VERSION "ZephyrECU CI fixtures"
NS_ :

BS_:
BU_: ECU Tester

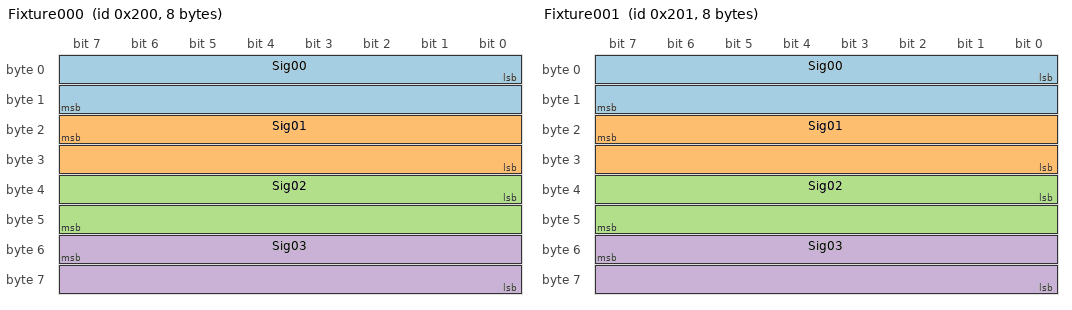
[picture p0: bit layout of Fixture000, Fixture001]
BO_ 512 Fixture000: 8 ECU
 SG_ Sig00 : 0|16@1+ (1,0) [0|65535] "" Tester
 SG_ Sig01 : 23|16@0- (1,0) [-32768|32767] "" Tester
 SG_ Sig02 : 32|16@1+ (1,0) [0|65535] "" Tester
 SG_ Sig03 : 55|16@0- (1,0) [-32768|32767] "" Tester

BO_ 513 Fixture001: 8 Tester
 SG_ Sig00 : 0|16@1+ (1,0) [0|65535] "" ECU
 SG_ Sig01 : 23|16@0- (1,0) [-32768|32767] "" ECU
 SG_ Sig02 : 32|16@1+ (1,0) [0|65535] "" ECU
 SG_ Sig03 : 55|16@0- (1,0) [-32768|32767] "" ECU

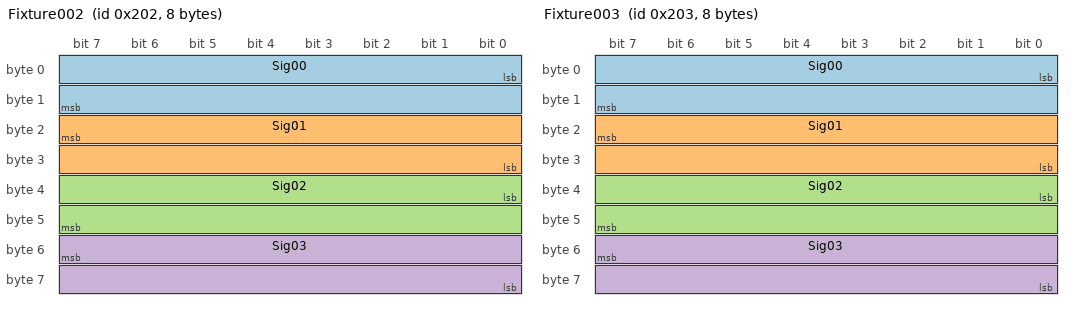
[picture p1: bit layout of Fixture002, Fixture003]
BO_ 514 Fixture002: 8 ECU
 SG_ Sig00 : 0|16@1+ (1,0) [0|65535] "" Tester
 SG_ Sig01 : 23|16@0- (1,0) [-32768|32767] "" Tester
 SG_ Sig02 : 32|16@1+ (1,0) [0|65535] "" Tester
 SG_ Sig03 : 55|16@0- (1,0) [-32768|32767] "" Tester

BO_ 515 Fixture003: 8 Tester
 SG_ Sig00 : 0|16@1+ (1,0) [0|65535] "" ECU
 SG_ Sig01 : 23|16@0- (1,0) [-32768|32767] "" ECU
 SG_ Sig02 : 32|16@1+ (1,0) [0|65535] "" ECU
 SG_ Sig03 : 55|16@0- (1,0) [-32768|32767] "" ECU

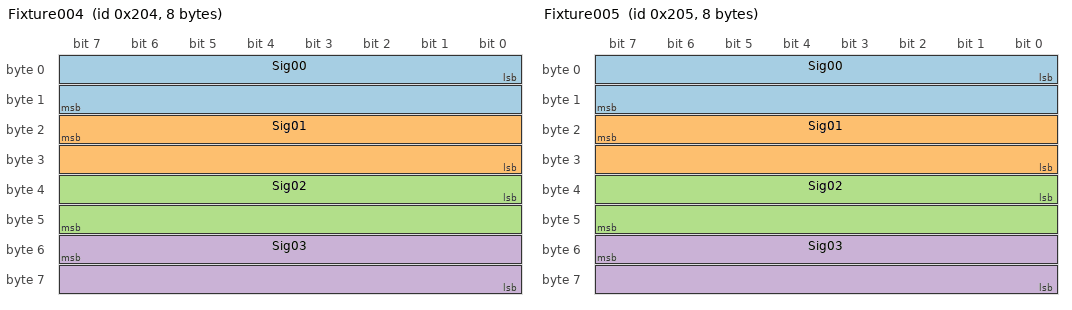
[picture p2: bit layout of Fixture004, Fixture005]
BO_ 516 Fixture004: 8 ECU
 SG_ Sig00 : 0|16@1+ (1,0) [0|65535] "" Tester
 SG_ Sig01 : 23|16@0- (1,0) [-32768|32767] "" Tester
 SG_ Sig02 : 32|16@1+ (1,0) [0|65535] "" Tester
 SG_ Sig03 : 55|16@0- (1,0) [-32768|32767] "" Tester

BO_ 517 Fixture005: 8 Tester
 SG_ Sig00 : 0|16@1+ (1,0) [0|65535] "" ECU
 SG_ Sig01 : 23|16@0- (1,0) [-32768|32767] "" ECU
 SG_ Sig02 : 32|16@1+ (1,0) [0|65535] "" ECU
 SG_ Sig03 : 55|16@0- (1,0) [-32768|32767] "" ECU

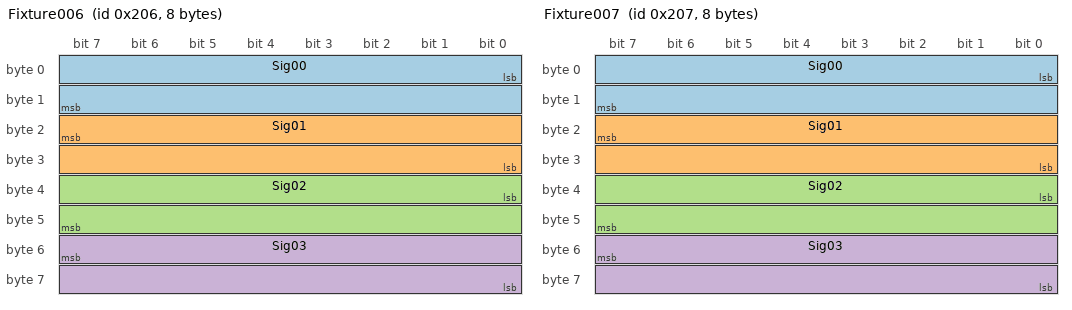
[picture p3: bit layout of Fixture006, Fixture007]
BO_ 518 Fixture006: 8 ECU
 SG_ Sig00 : 0|16@1+ (1,0) [0|65535] "" Tester
 SG_ Sig01 : 23|16@0- (1,0) [-32768|32767] "" Tester
 SG_ Sig02 : 32|16@1+ (1,0) [0|65535] "" Tester
 SG_ Sig03 : 55|16@0- (1,0) [-32768|32767] "" Tester

BO_ 519 Fixture007: 8 Tester
 SG_ Sig00 : 0|16@1+ (1,0) [0|65535] "" ECU
 SG_ Sig01 : 23|16@0- (1,0) [-32768|32767] "" ECU
 SG_ Sig02 : 32|16@1+ (1,0) [0|65535] "" ECU
 SG_ Sig03 : 55|16@0- (1,0) [-32768|32767] "" ECU

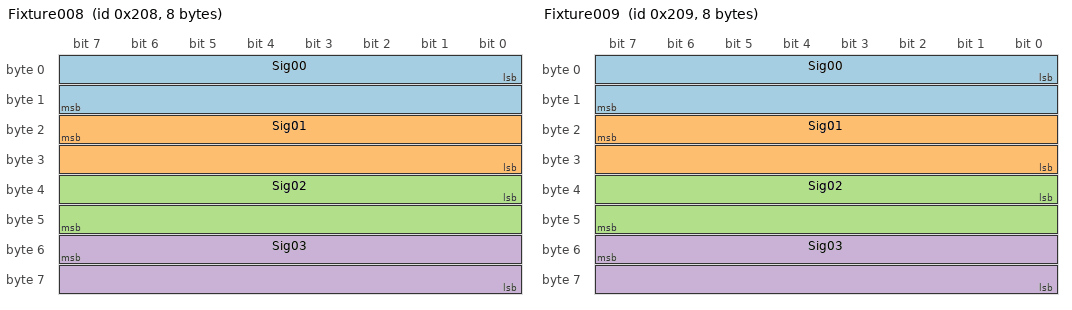
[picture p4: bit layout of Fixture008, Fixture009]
BO_ 520 Fixture008: 8 ECU
 SG_ Sig00 : 0|16@1+ (1,0) [0|65535] "" Tester
 SG_ Sig01 : 23|16@0- (1,0) [-32768|32767] "" Tester
 SG_ Sig02 : 32|16@1+ (1,0) [0|65535] "" Tester
 SG_ Sig03 : 55|16@0- (1,0) [-32768|32767] "" Tester

BO_ 521 Fixture009: 8 Tester
 SG_ Sig00 : 0|16@1+ (1,0) [0|65535] "" ECU
 SG_ Sig01 : 23|16@0- (1,0) [-32768|32767] "" ECU
 SG_ Sig02 : 32|16@1+ (1,0) [0|65535] "" ECU
 SG_ Sig03 : 55|16@0- (1,0) [-32768|32767] "" ECU

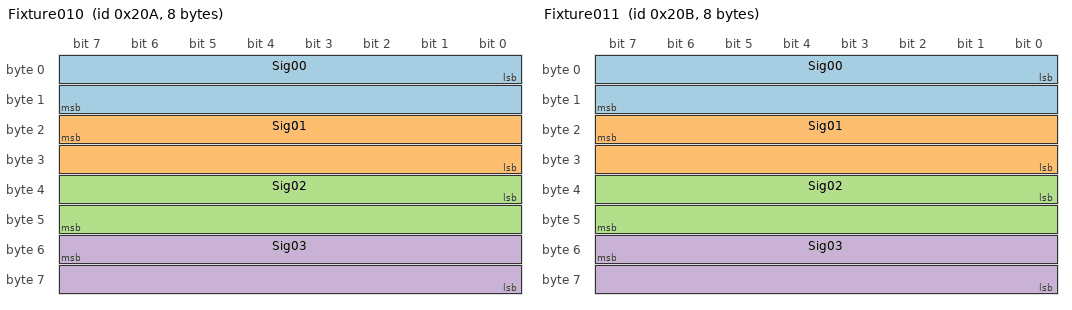
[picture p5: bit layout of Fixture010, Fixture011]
BO_ 522 Fixture010: 8 ECU
 SG_ Sig00 : 0|16@1+ (1,0) [0|65535] "" Tester
 SG_ Sig01 : 23|16@0- (1,0) [-32768|32767] "" Tester
 SG_ Sig02 : 32|16@1+ (1,0) [0|65535] "" Tester
 SG_ Sig03 : 55|16@0- (1,0) [-32768|32767] "" Tester

BO_ 523 Fixture011: 8 Tester
 SG_ Sig00 : 0|16@1+ (1,0) [0|65535] "" ECU
 SG_ Sig01 : 23|16@0- (1,0) [-32768|32767] "" ECU
 SG_ Sig02 : 32|16@1+ (1,0) [0|65535] "" ECU
 SG_ Sig03 : 55|16@0- (1,0) [-32768|32767] "" ECU

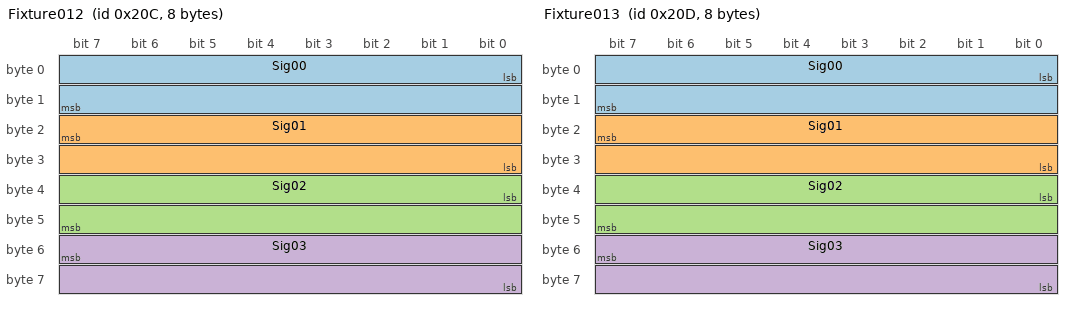
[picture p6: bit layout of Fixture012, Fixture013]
BO_ 524 Fixture012: 8 ECU
 SG_ Sig00 : 0|16@1+ (1,0) [0|65535] "" Tester
 SG_ Sig01 : 23|16@0- (1,0) [-32768|32767] "" Tester
 SG_ Sig02 : 32|16@1+ (1,0) [0|65535] "" Tester
 SG_ Sig03 : 55|16@0- (1,0) [-32768|32767] "" Tester

BO_ 525 Fixture013: 8 Tester
 SG_ Sig00 : 0|16@1+ (1,0) [0|65535] "" ECU
 SG_ Sig01 : 23|16@0- (1,0) [-32768|32767] "" ECU
 SG_ Sig02 : 32|16@1+ (1,0) [0|65535] "" ECU
 SG_ Sig03 : 55|16@0- (1,0) [-32768|32767] "" ECU

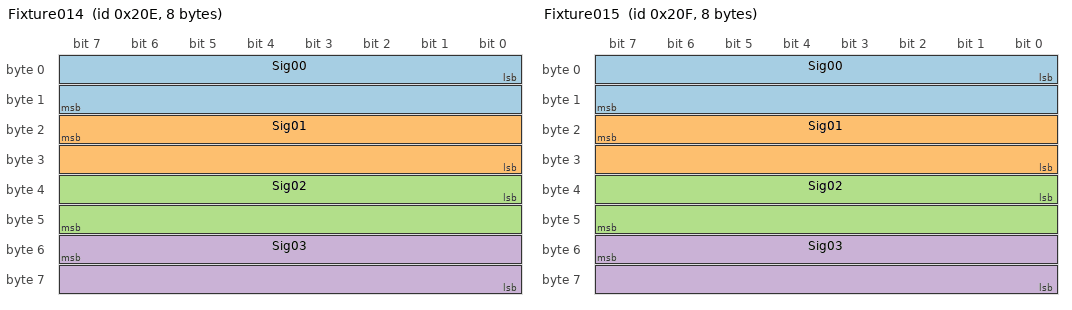
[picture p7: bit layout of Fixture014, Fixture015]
BO_ 526 Fixture014: 8 ECU
 SG_ Sig00 : 0|16@1+ (1,0) [0|65535] "" Tester
 SG_ Sig01 : 23|16@0- (1,0) [-32768|32767] "" Tester
 SG_ Sig02 : 32|16@1+ (1,0) [0|65535] "" Tester
 SG_ Sig03 : 55|16@0- (1,0) [-32768|32767] "" Tester

BO_ 527 Fixture015: 8 Tester
 SG_ Sig00 : 0|16@1+ (1,0) [0|65535] "" ECU
 SG_ Sig01 : 23|16@0- (1,0) [-32768|32767] "" ECU
 SG_ Sig02 : 32|16@1+ (1,0) [0|65535] "" ECU
 SG_ Sig03 : 55|16@0- (1,0) [-32768|32767] "" ECU

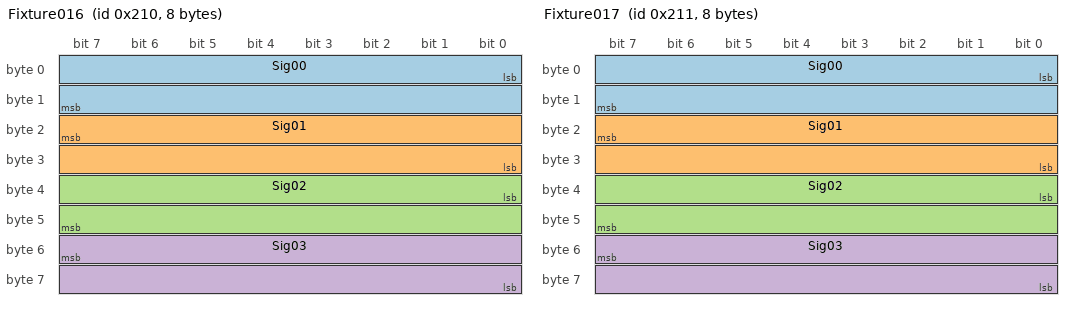
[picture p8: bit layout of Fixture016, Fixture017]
BO_ 528 Fixture016: 8 ECU
 SG_ Sig00 : 0|16@1+ (1,0) [0|65535] "" Tester
 SG_ Sig01 : 23|16@0- (1,0) [-32768|32767] "" Tester
 SG_ Sig02 : 32|16@1+ (1,0) [0|65535] "" Tester
 SG_ Sig03 : 55|16@0- (1,0) [-32768|32767] "" Tester

BO_ 529 Fixture017: 8 Tester
 SG_ Sig00 : 0|16@1+ (1,0) [0|65535] "" ECU
 SG_ Sig01 : 23|16@0- (1,0) [-32768|32767] "" ECU
 SG_ Sig02 : 32|16@1+ (1,0) [0|65535] "" ECU
 SG_ Sig03 : 55|16@0- (1,0) [-32768|32767] "" ECU

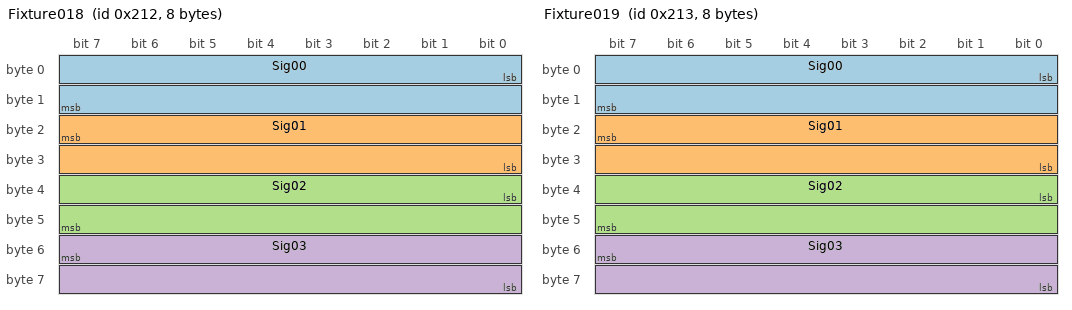
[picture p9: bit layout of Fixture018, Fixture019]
BO_ 530 Fixture018: 8 ECU
 SG_ Sig00 : 0|16@1+ (1,0) [0|65535] "" Tester
 SG_ Sig01 : 23|16@0- (1,0) [-32768|32767] "" Tester
 SG_ Sig02 : 32|16@1+ (1,0) [0|65535] "" Tester
 SG_ Sig03 : 55|16@0- (1,0) [-32768|32767] "" Tester

BO_ 531 Fixture019: 8 Tester
 SG_ Sig00 : 0|16@1+ (1,0) [0|65535] "" ECU
 SG_ Sig01 : 23|16@0- (1,0) [-32768|32767] "" ECU
 SG_ Sig02 : 32|16@1+ (1,0) [0|65535] "" ECU
 SG_ Sig03 : 55|16@0- (1,0) [-32768|32767] "" ECU

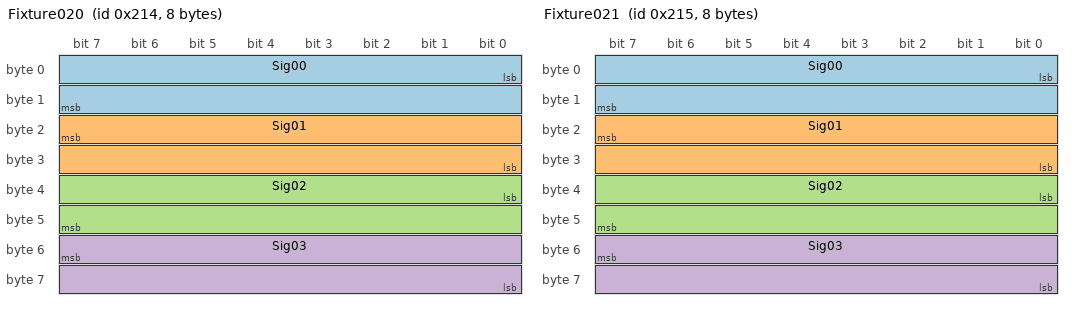
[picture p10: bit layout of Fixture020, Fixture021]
BO_ 532 Fixture020: 8 ECU
 SG_ Sig00 : 0|16@1+ (1,0) [0|65535] "" Tester
 SG_ Sig01 : 23|16@0- (1,0) [-32768|32767] "" Tester
 SG_ Sig02 : 32|16@1+ (1,0) [0|65535] "" Tester
 SG_ Sig03 : 55|16@0- (1,0) [-32768|32767] "" Tester

BO_ 533 Fixture021: 8 Tester
 SG_ Sig00 : 0|16@1+ (1,0) [0|65535] "" ECU
 SG_ Sig01 : 23|16@0- (1,0) [-32768|32767] "" ECU
 SG_ Sig02 : 32|16@1+ (1,0) [0|65535] "" ECU
 SG_ Sig03 : 55|16@0- (1,0) [-32768|32767] "" ECU

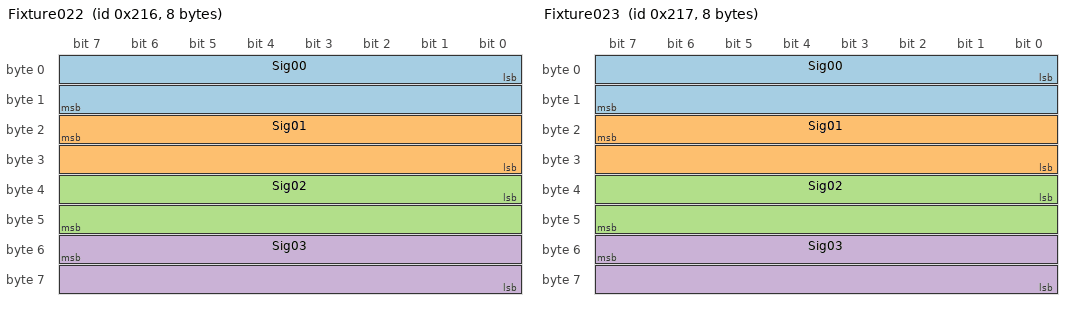
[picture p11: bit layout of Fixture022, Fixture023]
BO_ 534 Fixture022: 8 ECU
 SG_ Sig00 : 0|16@1+ (1,0) [0|65535] "" Tester
 SG_ Sig01 : 23|16@0- (1,0) [-32768|32767] "" Tester
 SG_ Sig02 : 32|16@1+ (1,0) [0|65535] "" Tester
 SG_ Sig03 : 55|16@0- (1,0) [-32768|32767] "" Tester

BO_ 535 Fixture023: 8 Tester
 SG_ Sig00 : 0|16@1+ (1,0) [0|65535] "" ECU
 SG_ Sig01 : 23|16@0- (1,0) [-32768|32767] "" ECU
 SG_ Sig02 : 32|16@1+ (1,0) [0|65535] "" ECU
 SG_ Sig03 : 55|16@0- (1,0) [-32768|32767] "" ECU

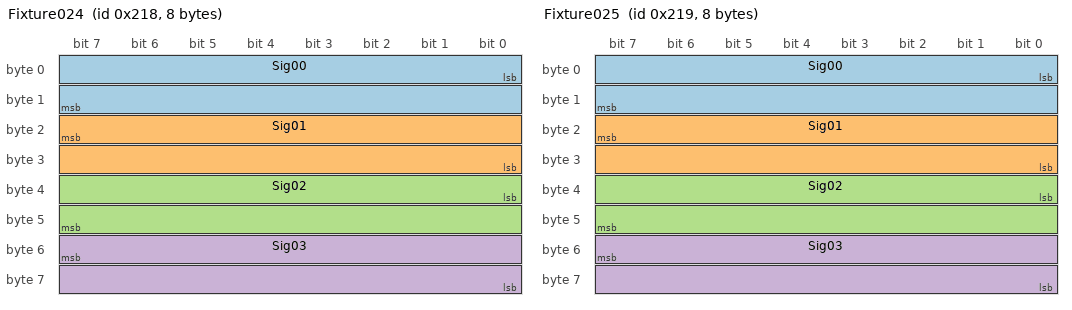
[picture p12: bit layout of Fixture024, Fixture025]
BO_ 536 Fixture024: 8 ECU
 SG_ Sig00 : 0|16@1+ (1,0) [0|65535] "" Tester
 SG_ Sig01 : 23|16@0- (1,0) [-32768|32767] "" Tester
 SG_ Sig02 : 32|16@1+ (1,0) [0|65535] "" Tester
 SG_ Sig03 : 55|16@0- (1,0) [-32768|32767] "" Tester

BO_ 537 Fixture025: 8 Tester
 SG_ Sig00 : 0|16@1+ (1,0) [0|65535] "" ECU
 SG_ Sig01 : 23|16@0- (1,0) [-32768|32767] "" ECU
 SG_ Sig02 : 32|16@1+ (1,0) [0|65535] "" ECU
 SG_ Sig03 : 55|16@0- (1,0) [-32768|32767] "" ECU

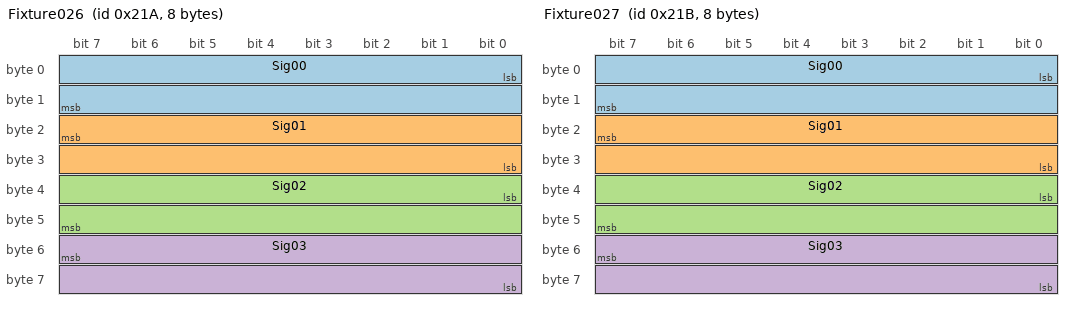
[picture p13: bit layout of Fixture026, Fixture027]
BO_ 538 Fixture026: 8 ECU
 SG_ Sig00 : 0|16@1+ (1,0) [0|65535] "" Tester
 SG_ Sig01 : 23|16@0- (1,0) [-32768|32767] "" Tester
 SG_ Sig02 : 32|16@1+ (1,0) [0|65535] "" Tester
 SG_ Sig03 : 55|16@0- (1,0) [-32768|32767] "" Tester

BO_ 539 Fixture027: 8 Tester
 SG_ Sig00 : 0|16@1+ (1,0) [0|65535] "" ECU
 SG_ Sig01 : 23|16@0- (1,0) [-32768|32767] "" ECU
 SG_ Sig02 : 32|16@1+ (1,0) [0|65535] "" ECU
 SG_ Sig03 : 55|16@0- (1,0) [-32768|32767] "" ECU

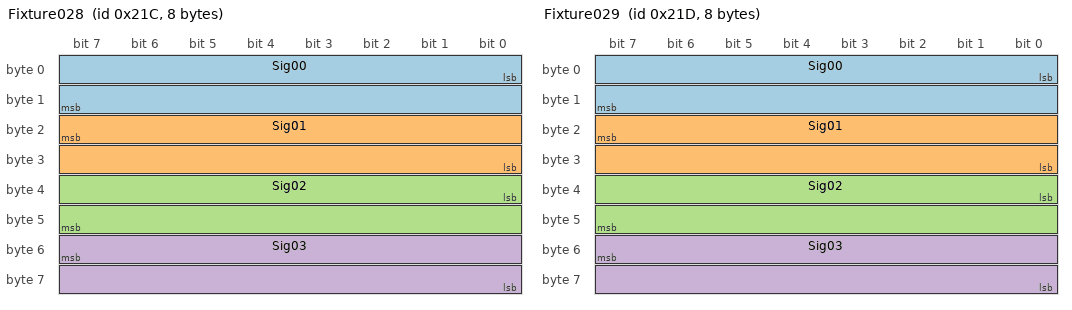
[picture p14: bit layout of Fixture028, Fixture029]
BO_ 540 Fixture028: 8 ECU
 SG_ Sig00 : 0|16@1+ (1,0) [0|65535] "" Tester
 SG_ Sig01 : 23|16@0- (1,0) [-32768|32767] "" Tester
 SG_ Sig02 : 32|16@1+ (1,0) [0|65535] "" Tester
 SG_ Sig03 : 55|16@0- (1,0) [-32768|32767] "" Tester

BO_ 541 Fixture029: 8 Tester
 SG_ Sig00 : 0|16@1+ (1,0) [0|65535] "" ECU
 SG_ Sig01 : 23|16@0- (1,0) [-32768|32767] "" ECU
 SG_ Sig02 : 32|16@1+ (1,0) [0|65535] "" ECU
 SG_ Sig03 : 55|16@0- (1,0) [-32768|32767] "" ECU

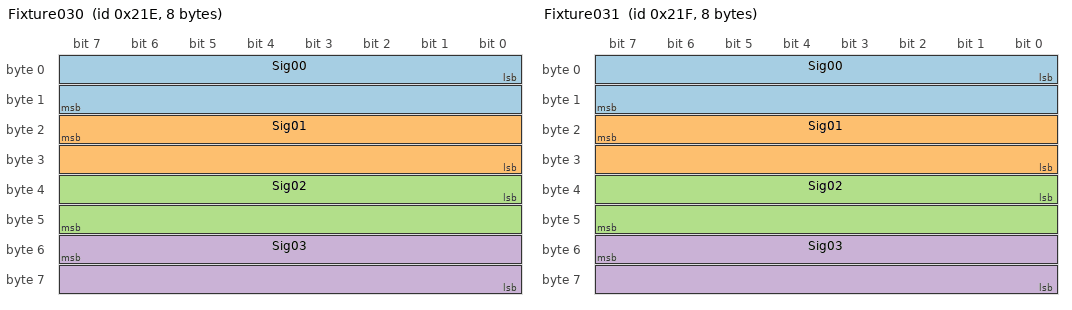
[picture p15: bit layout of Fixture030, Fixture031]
BO_ 542 Fixture030: 8 ECU
 SG_ Sig00 : 0|16@1+ (1,0) [0|65535] "" Tester
 SG_ Sig01 : 23|16@0- (1,0) [-32768|32767] "" Tester
 SG_ Sig02 : 32|16@1+ (1,0) [0|65535] "" Tester
 SG_ Sig03 : 55|16@0- (1,0) [-32768|32767] "" Tester

BO_ 543 Fixture031: 8 Tester
 SG_ Sig00 : 0|16@1+ (1,0) [0|65535] "" ECU
 SG_ Sig01 : 23|16@0- (1,0) [-32768|32767] "" ECU
 SG_ Sig02 : 32|16@1+ (1,0) [0|65535] "" ECU
 SG_ Sig03 : 55|16@0- (1,0) [-32768|32767] "" ECU

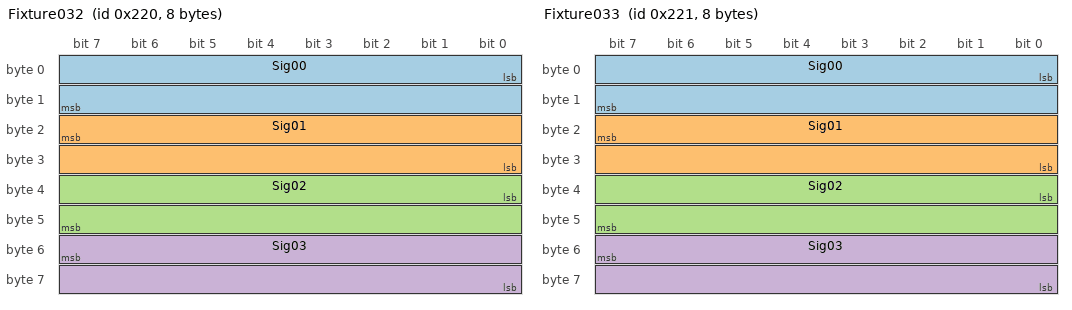
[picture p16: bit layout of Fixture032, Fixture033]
BO_ 544 Fixture032: 8 ECU
 SG_ Sig00 : 0|16@1+ (1,0) [0|65535] "" Tester
 SG_ Sig01 : 23|16@0- (1,0) [-32768|32767] "" Tester
 SG_ Sig02 : 32|16@1+ (1,0) [0|65535] "" Tester
 SG_ Sig03 : 55|16@0- (1,0) [-32768|32767] "" Tester

BO_ 545 Fixture033: 8 Tester
 SG_ Sig00 : 0|16@1+ (1,0) [0|65535] "" ECU
 SG_ Sig01 : 23|16@0- (1,0) [-32768|32767] "" ECU
 SG_ Sig02 : 32|16@1+ (1,0) [0|65535] "" ECU
 SG_ Sig03 : 55|16@0- (1,0) [-32768|32767] "" ECU

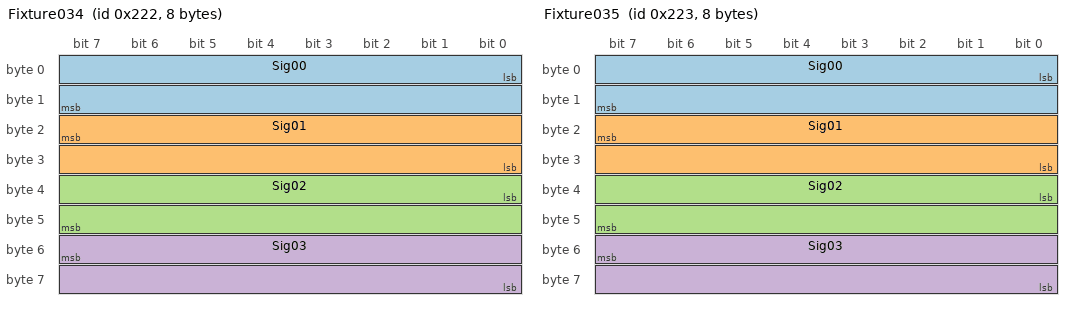
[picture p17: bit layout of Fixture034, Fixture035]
BO_ 546 Fixture034: 8 ECU
 SG_ Sig00 : 0|16@1+ (1,0) [0|65535] "" Tester
 SG_ Sig01 : 23|16@0- (1,0) [-32768|32767] "" Tester
 SG_ Sig02 : 32|16@1+ (1,0) [0|65535] "" Tester
 SG_ Sig03 : 55|16@0- (1,0) [-32768|32767] "" Tester

BO_ 547 Fixture035: 8 Tester
 SG_ Sig00 : 0|16@1+ (1,0) [0|65535] "" ECU
 SG_ Sig01 : 23|16@0- (1,0) [-32768|32767] "" ECU
 SG_ Sig02 : 32|16@1+ (1,0) [0|65535] "" ECU
 SG_ Sig03 : 55|16@0- (1,0) [-32768|32767] "" ECU

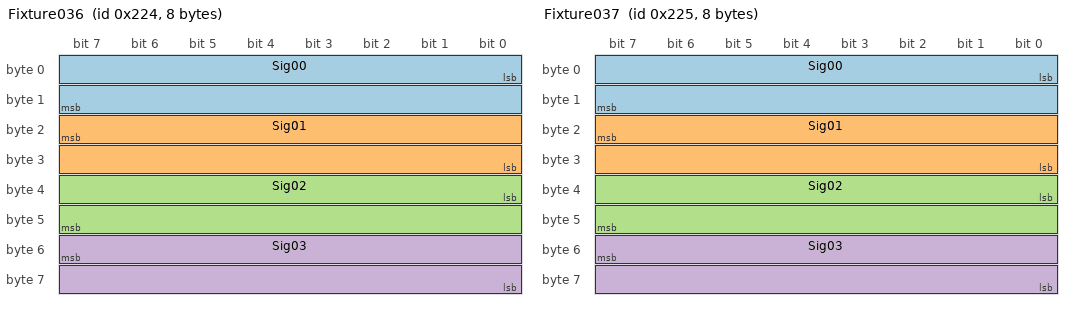
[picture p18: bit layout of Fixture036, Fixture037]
BO_ 548 Fixture036: 8 ECU
 SG_ Sig00 : 0|16@1+ (1,0) [0|65535] "" Tester
 SG_ Sig01 : 23|16@0- (1,0) [-32768|32767] "" Tester
 SG_ Sig02 : 32|16@1+ (1,0) [0|65535] "" Tester
 SG_ Sig03 : 55|16@0- (1,0) [-32768|32767] "" Tester

BO_ 549 Fixture037: 8 Tester
 SG_ Sig00 : 0|16@1+ (1,0) [0|65535] "" ECU
 SG_ Sig01 : 23|16@0- (1,0) [-32768|32767] "" ECU
 SG_ Sig02 : 32|16@1+ (1,0) [0|65535] "" ECU
 SG_ Sig03 : 55|16@0- (1,0) [-32768|32767] "" ECU

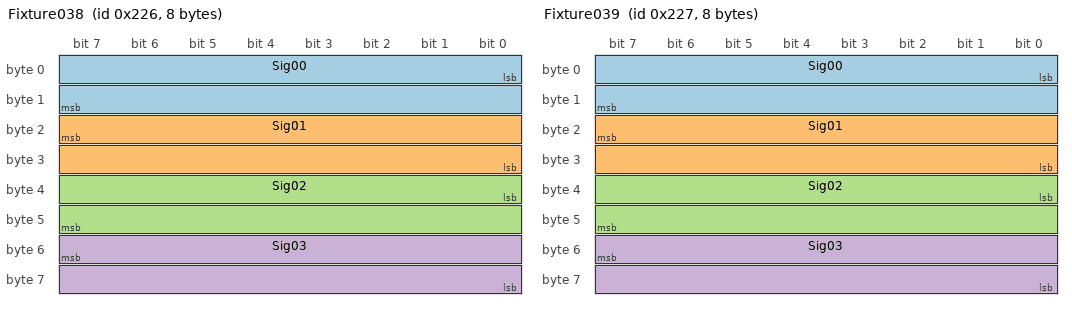
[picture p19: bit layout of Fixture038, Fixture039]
BO_ 550 Fixture038: 8 ECU
 SG_ Sig00 : 0|16@1+ (1,0) [0|65535] "" Tester
 SG_ Sig01 : 23|16@0- (1,0) [-32768|32767] "" Tester
 SG_ Sig02 : 32|16@1+ (1,0) [0|65535] "" Tester
 SG_ Sig03 : 55|16@0- (1,0) [-32768|32767] "" Tester

BO_ 551 Fixture039: 8 Tester
 SG_ Sig00 : 0|16@1+ (1,0) [0|65535] "" ECU
 SG_ Sig01 : 23|16@0- (1,0) [-32768|32767] "" ECU
 SG_ Sig02 : 32|16@1+ (1,0) [0|65535] "" ECU
 SG_ Sig03 : 55|16@0- (1,0) [-32768|32767] "" ECU

BO_ 552 Fixture040: 8 ECU
 SG_ Sig00 : 0|16@1+ (1,0) [0|65535] "" Tester
 SG_ Sig01 : 23|16@0- (1,0) [-32768|32767] "" Tester
 SG_ Sig02 : 32|16@1+ (1,0) [0|65535] "" Tester
 SG_ Sig03 : 55|16@0- (1,0) [-32768|32767] "" Tester

BO_ 553 Fixture041: 8 Tester
 SG_ Sig00 : 0|16@1+ (1,0) [0|65535] "" ECU
 SG_ Sig01 : 23|16@0- (1,0) [-32768|32767] "" ECU
 SG_ Sig02 : 32|16@1+ (1,0) [0|65535] "" ECU
 SG_ Sig03 : 55|16@0- (1,0) [-32768|32767] "" ECU

BO_ 554 Fixture042: 8 ECU
 SG_ Sig00 : 0|16@1+ (1,0) [0|65535] "" Tester
 SG_ Sig01 : 23|16@0- (1,0) [-32768|32767] "" Tester
 SG_ Sig02 : 32|16@1+ (1,0) [0|65535] "" Tester
 SG_ Sig03 : 55|16@0- (1,0) [-32768|32767] "" Tester

BO_ 555 Fixture043: 8 Tester
 SG_ Sig00 : 0|16@1+ (1,0) [0|65535] "" ECU
 SG_ Sig01 : 23|16@0- (1,0) [-32768|32767] "" ECU
 SG_ Sig02 : 32|16@1+ (1,0) [0|65535] "" ECU
 SG_ Sig03 : 55|16@0- (1,0) [-32768|32767] "" ECU

BO_ 556 Fixture044: 8 ECU
 SG_ Sig00 : 0|16@1+ (1,0) [0|65535] "" Tester
 SG_ Sig01 : 23|16@0- (1,0) [-32768|32767] "" Tester
 SG_ Sig02 : 32|16@1+ (1,0) [0|65535] "" Tester
 SG_ Sig03 : 55|16@0- (1,0) [-32768|32767] "" Tester

BO_ 557 Fixture045: 8 Tester
 SG_ Sig00 : 0|16@1+ (1,0) [0|65535] "" ECU
 SG_ Sig01 : 23|16@0- (1,0) [-32768|32767] "" ECU
 SG_ Sig02 : 32|16@1+ (1,0) [0|65535] "" ECU
 SG_ Sig03 : 55|16@0- (1,0) [-32768|32767] "" ECU

BO_ 558 Fixture046: 8 ECU
 SG_ Sig00 : 0|16@1+ (1,0) [0|65535] "" Tester
 SG_ Sig01 : 23|16@0- (1,0) [-32768|32767] "" Tester
 SG_ Sig02 : 32|16@1+ (1,0) [0|65535] "" Tester
 SG_ Sig03 : 55|16@0- (1,0) [-32768|32767] "" Tester

BO_ 559 Fixture047: 8 Tester
 SG_ Sig00 : 0|16@1+ (1,0) [0|65535] "" ECU
 SG_ Sig01 : 23|16@0- (1,0) [-32768|32767] "" ECU
 SG_ Sig02 : 32|16@1+ (1,0) [0|65535] "" ECU
 SG_ Sig03 : 55|16@0- (1,0) [-32768|32767] "" ECU

BO_ 560 Fixture048: 8 ECU
 SG_ Sig00 : 0|16@1+ (1,0) [0|65535] "" Tester
 SG_ Sig01 : 23|16@0- (1,0) [-32768|32767] "" Tester
 SG_ Sig02 : 32|16@1+ (1,0) [0|65535] "" Tester
 SG_ Sig03 : 55|16@0- (1,0) [-32768|32767] "" Tester

BO_ 561 Fixture049: 8 Tester
 SG_ Sig00 : 0|16@1+ (1,0) [0|65535] "" ECU
 SG_ Sig01 : 23|16@0- (1,0) [-32768|32767] "" ECU
 SG_ Sig02 : 32|16@1+ (1,0) [0|65535] "" ECU
 SG_ Sig03 : 55|16@0- (1,0) [-32768|32767] "" ECU

BO_ 562 Fixture050: 8 ECU
 SG_ Sig00 : 0|16@1+ (1,0) [0|65535] "" Tester
 SG_ Sig01 : 23|16@0- (1,0) [-32768|32767] "" Tester
 SG_ Sig02 : 32|16@1+ (1,0) [0|65535] "" Tester
 SG_ Sig03 : 55|16@0- (1,0) [-32768|32767] "" Tester

BO_ 563 Fixture051: 8 Tester
 SG_ Sig00 : 0|16@1+ (1,0) [0|65535] "" ECU
 SG_ Sig01 : 23|16@0- (1,0) [-32768|32767] "" ECU
 SG_ Sig02 : 32|16@1+ (1,0) [0|65535] "" ECU
 SG_ Sig03 : 55|16@0- (1,0) [-32768|32767] "" ECU

BO_ 564 Fixture052: 8 ECU
 SG_ Sig00 : 0|16@1+ (1,0) [0|65535] "" Tester
 SG_ Sig01 : 23|16@0- (1,0) [-32768|32767] "" Tester
 SG_ Sig02 : 32|16@1+ (1,0) [0|65535] "" Tester
 SG_ Sig03 : 55|16@0- (1,0) [-32768|32767] "" Tester

BO_ 565 Fixture053: 8 Tester
 SG_ Sig00 : 0|16@1+ (1,0) [0|65535] "" ECU
 SG_ Sig01 : 23|16@0- (1,0) [-32768|32767] "" ECU
 SG_ Sig02 : 32|16@1+ (1,0) [0|65535] "" ECU
 SG_ Sig03 : 55|16@0- (1,0) [-32768|32767] "" ECU

BO_ 566 Fixture054: 8 ECU
 SG_ Sig00 : 0|16@1+ (1,0) [0|65535] "" Tester
 SG_ Sig01 : 23|16@0- (1,0) [-32768|32767] "" Tester
 SG_ Sig02 : 32|16@1+ (1,0) [0|65535] "" Tester
 SG_ Sig03 : 55|16@0- (1,0) [-32768|32767] "" Tester

BO_ 567 Fixture055: 8 Tester
 SG_ Sig00 : 0|16@1+ (1,0) [0|65535] "" ECU
 SG_ Sig01 : 23|16@0- (1,0) [-32768|32767] "" ECU
 SG_ Sig02 : 32|16@1+ (1,0) [0|65535] "" ECU
 SG_ Sig03 : 55|16@0- (1,0) [-32768|32767] "" ECU

BO_ 568 Fixture056: 8 ECU
 SG_ Sig00 : 0|16@1+ (1,0) [0|65535] "" Tester
 SG_ Sig01 : 23|16@0- (1,0) [-32768|32767] "" Tester
 SG_ Sig02 : 32|16@1+ (1,0) [0|65535] "" Tester
 SG_ Sig03 : 55|16@0- (1,0) [-32768|32767] "" Tester

BO_ 569 Fixture057: 8 Tester
 SG_ Sig00 : 0|16@1+ (1,0) [0|65535] "" ECU
 SG_ Sig01 : 23|16@0- (1,0) [-32768|32767] "" ECU
 SG_ Sig02 : 32|16@1+ (1,0) [0|65535] "" ECU
 SG_ Sig03 : 55|16@0- (1,0) [-32768|32767] "" ECU

BO_ 570 Fixture058: 8 ECU
 SG_ Sig00 : 0|16@1+ (1,0) [0|65535] "" Tester
 SG_ Sig01 : 23|16@0- (1,0) [-32768|32767] "" Tester
 SG_ Sig02 : 32|16@1+ (1,0) [0|65535] "" Tester
 SG_ Sig03 : 55|16@0- (1,0) [-32768|32767] "" Tester

BO_ 571 Fixture059: 8 Tester
 SG_ Sig00 : 0|16@1+ (1,0) [0|65535] "" ECU
 SG_ Sig01 : 23|16@0- (1,0) [-32768|32767] "" ECU
 SG_ Sig02 : 32|16@1+ (1,0) [0|65535] "" ECU
 SG_ Sig03 : 55|16@0- (1,0) [-32768|32767] "" ECU

BO_ 572 Fixture060: 8 ECU
 SG_ Sig00 : 0|16@1+ (1,0) [0|65535] "" Tester
 SG_ Sig01 : 23|16@0- (1,0) [-32768|32767] "" Tester
 SG_ Sig02 : 32|16@1+ (1,0) [0|65535] "" Tester
 SG_ Sig03 : 55|16@0- (1,0) [-32768|32767] "" Tester

BO_ 573 Fixture061: 8 Tester
 SG_ Sig00 : 0|16@1+ (1,0) [0|65535] "" ECU
 SG_ Sig01 : 23|16@0- (1,0) [-32768|32767] "" ECU
 SG_ Sig02 : 32|16@1+ (1,0) [0|65535] "" ECU
 SG_ Sig03 : 55|16@0- (1,0) [-32768|32767] "" ECU

BO_ 574 Fixture062: 8 ECU
 SG_ Sig00 : 0|16@1+ (1,0) [0|65535] "" Tester
 SG_ Sig01 : 23|16@0- (1,0) [-32768|32767] "" Tester
 SG_ Sig02 : 32|16@1+ (1,0) [0|65535] "" Tester
 SG_ Sig03 : 55|16@0- (1,0) [-32768|32767] "" Tester

BO_ 575 Fixture063: 8 Tester
 SG_ Sig00 : 0|16@1+ (1,0) [0|65535] "" ECU
 SG_ Sig01 : 23|16@0- (1,0) [-32768|32767] "" ECU
 SG_ Sig02 : 32|16@1+ (1,0) [0|65535] "" ECU
 SG_ Sig03 : 55|16@0- (1,0) [-32768|32767] "" ECU

BO_ 576 Fixture064: 8 ECU
 SG_ Sig00 : 0|16@1+ (1,0) [0|65535] "" Tester
 SG_ Sig01 : 23|16@0- (1,0) [-32768|32767] "" Tester
 SG_ Sig02 : 32|16@1+ (1,0) [0|65535] "" Tester
 SG_ Sig03 : 55|16@0- (1,0) [-32768|32767] "" Tester

BO_ 577 Fixture065: 8 Tester
 SG_ Sig00 : 0|16@1+ (1,0) [0|65535] "" ECU
 SG_ Sig01 : 23|16@0- (1,0) [-32768|32767] "" ECU
 SG_ Sig02 : 32|16@1+ (1,0) [0|65535] "" ECU
 SG_ Sig03 : 55|16@0- (1,0) [-32768|32767] "" ECU

BO_ 578 Fixture066: 8 ECU
 SG_ Sig00 : 0|16@1+ (1,0) [0|65535] "" Tester
 SG_ Sig01 : 23|16@0- (1,0) [-32768|32767] "" Tester
 SG_ Sig02 : 32|16@1+ (1,0) [0|65535] "" Tester
 SG_ Sig03 : 55|16@0- (1,0) [-32768|32767] "" Tester

BO_ 579 Fixture067: 8 Tester
 SG_ Sig00 : 0|16@1+ (1,0) [0|65535] "" ECU
 SG_ Sig01 : 23|16@0- (1,0) [-32768|32767] "" ECU
 SG_ Sig02 : 32|16@1+ (1,0) [0|65535] "" ECU
 SG_ Sig03 : 55|16@0- (1,0) [-32768|32767] "" ECU

BO_ 580 Fixture068: 8 ECU
 SG_ Sig00 : 0|16@1+ (1,0) [0|65535] "" Tester
 SG_ Sig01 : 23|16@0- (1,0) [-32768|32767] "" Tester
 SG_ Sig02 : 32|16@1+ (1,0) [0|65535] "" Tester
 SG_ Sig03 : 55|16@0- (1,0) [-32768|32767] "" Tester

BO_ 581 Fixture069: 8 Tester
 SG_ Sig00 : 0|16@1+ (1,0) [0|65535] "" ECU
 SG_ Sig01 : 23|16@0- (1,0) [-32768|32767] "" ECU
 SG_ Sig02 : 32|16@1+ (1,0) [0|65535] "" ECU
 SG_ Sig03 : 55|16@0- (1,0) [-32768|32767] "" ECU

BO_ 582 Fixture070: 8 ECU
 SG_ Sig00 : 0|16@1+ (1,0) [0|65535] "" Tester
 SG_ Sig01 : 23|16@0- (1,0) [-32768|32767] "" Tester
 SG_ Sig02 : 32|16@1+ (1,0) [0|65535] "" Tester
 SG_ Sig03 : 55|16@0- (1,0) [-32768|32767] "" Tester

BO_ 583 Fixture071: 8 Tester
 SG_ Sig00 : 0|16@1+ (1,0) [0|65535] "" ECU
 SG_ Sig01 : 23|16@0- (1,0) [-32768|32767] "" ECU
 SG_ Sig02 : 32|16@1+ (1,0) [0|65535] "" ECU
 SG_ Sig03 : 55|16@0- (1,0) [-32768|32767] "" ECU

BO_ 584 Fixture072: 8 ECU
 SG_ Sig00 : 0|16@1+ (1,0) [0|65535] "" Tester
 SG_ Sig01 : 23|16@0- (1,0) [-32768|32767] "" Tester
 SG_ Sig02 : 32|16@1+ (1,0) [0|65535] "" Tester
 SG_ Sig03 : 55|16@0- (1,0) [-32768|32767] "" Tester

BO_ 585 Fixture073: 8 Tester
 SG_ Sig00 : 0|16@1+ (1,0) [0|65535] "" ECU
 SG_ Sig01 : 23|16@0- (1,0) [-32768|32767] "" ECU
 SG_ Sig02 : 32|16@1+ (1,0) [0|65535] "" ECU
 SG_ Sig03 : 55|16@0- (1,0) [-32768|32767] "" ECU

BO_ 586 Fixture074: 8 ECU
 SG_ Sig00 : 0|16@1+ (1,0) [0|65535] "" Tester
 SG_ Sig01 : 23|16@0- (1,0) [-32768|32767] "" Tester
 SG_ Sig02 : 32|16@1+ (1,0) [0|65535] "" Tester
 SG_ Sig03 : 55|16@0- (1,0) [-32768|32767] "" Tester

BO_ 587 Fixture075: 8 Tester
 SG_ Sig00 : 0|16@1+ (1,0) [0|65535] "" ECU
 SG_ Sig01 : 23|16@0- (1,0) [-32768|32767] "" ECU
 SG_ Sig02 : 32|16@1+ (1,0) [0|65535] "" ECU
 SG_ Sig03 : 55|16@0- (1,0) [-32768|32767] "" ECU

BO_ 588 Fixture076: 8 ECU
 SG_ Sig00 : 0|16@1+ (1,0) [0|65535] "" Tester
 SG_ Sig01 : 23|16@0- (1,0) [-32768|32767] "" Tester
 SG_ Sig02 : 32|16@1+ (1,0) [0|65535] "" Tester
 SG_ Sig03 : 55|16@0- (1,0) [-32768|32767] "" Tester

BO_ 589 Fixture077: 8 Tester
 SG_ Sig00 : 0|16@1+ (1,0) [0|65535] "" ECU
 SG_ Sig01 : 23|16@0- (1,0) [-32768|32767] "" ECU
 SG_ Sig02 : 32|16@1+ (1,0) [0|65535] "" ECU
 SG_ Sig03 : 55|16@0- (1,0) [-32768|32767] "" ECU

BO_ 590 Fixture078: 8 ECU
 SG_ Sig00 : 0|16@1+ (1,0) [0|65535] "" Tester
 SG_ Sig01 : 23|16@0- (1,0) [-32768|32767] "" Tester
 SG_ Sig02 : 32|16@1+ (1,0) [0|65535] "" Tester
 SG_ Sig03 : 55|16@0- (1,0) [-32768|32767] "" Tester

BO_ 591 Fixture079: 8 Tester
 SG_ Sig00 : 0|16@1+ (1,0) [0|65535] "" ECU
 SG_ Sig01 : 23|16@0- (1,0) [-32768|32767] "" ECU
 SG_ Sig02 : 32|16@1+ (1,0) [0|65535] "" ECU
 SG_ Sig03 : 55|16@0- (1,0) [-32768|32767] "" ECU

BO_ 592 Fixture080: 8 ECU
 SG_ Sig00 : 0|16@1+ (1,0) [0|65535] "" Tester
 SG_ Sig01 : 23|16@0- (1,0) [-32768|32767] "" Tester
 SG_ Sig02 : 32|16@1+ (1,0) [0|65535] "" Tester
 SG_ Sig03 : 55|16@0- (1,0) [-32768|32767] "" Tester

BO_ 593 Fixture081: 8 Tester
 SG_ Sig00 : 0|16@1+ (1,0) [0|65535] "" ECU
 SG_ Sig01 : 23|16@0- (1,0) [-32768|32767] "" ECU
 SG_ Sig02 : 32|16@1+ (1,0) [0|65535] "" ECU
 SG_ Sig03 : 55|16@0- (1,0) [-32768|32767] "" ECU

BO_ 594 Fixture082: 8 ECU
 SG_ Sig00 : 0|16@1+ (1,0) [0|65535] "" Tester
 SG_ Sig01 : 23|16@0- (1,0) [-32768|32767] "" Tester
 SG_ Sig02 : 32|16@1+ (1,0) [0|65535] "" Tester
 SG_ Sig03 : 55|16@0- (1,0) [-32768|32767] "" Tester

BO_ 595 Fixture083: 8 Tester
 SG_ Sig00 : 0|16@1+ (1,0) [0|65535] "" ECU
 SG_ Sig01 : 23|16@0- (1,0) [-32768|32767] "" ECU
 SG_ Sig02 : 32|16@1+ (1,0) [0|65535] "" ECU
 SG_ Sig03 : 55|16@0- (1,0) [-32768|32767] "" ECU

BO_ 596 Fixture084: 8 ECU
 SG_ Sig00 : 0|16@1+ (1,0) [0|65535] "" Tester
 SG_ Sig01 : 23|16@0- (1,0) [-32768|32767] "" Tester
 SG_ Sig02 : 32|16@1+ (1,0) [0|65535] "" Tester
 SG_ Sig03 : 55|16@0- (1,0) [-32768|32767] "" Tester

BO_ 597 Fixture085: 8 Tester
 SG_ Sig00 : 0|16@1+ (1,0) [0|65535] "" ECU
 SG_ Sig01 : 23|16@0- (1,0) [-32768|32767] "" ECU
 SG_ Sig02 : 32|16@1+ (1,0) [0|65535] "" ECU
 SG_ Sig03 : 55|16@0- (1,0) [-32768|32767] "" ECU

BO_ 598 Fixture086: 8 ECU
 SG_ Sig00 : 0|16@1+ (1,0) [0|65535] "" Tester
 SG_ Sig01 : 23|16@0- (1,0) [-32768|32767] "" Tester
 SG_ Sig02 : 32|16@1+ (1,0) [0|65535] "" Tester
 SG_ Sig03 : 55|16@0- (1,0) [-32768|32767] "" Tester

BO_ 599 Fixture087: 8 Tester
 SG_ Sig00 : 0|16@1+ (1,0) [0|65535] "" ECU
 SG_ Sig01 : 23|16@0- (1,0) [-32768|32767] "" ECU
 SG_ Sig02 : 32|16@1+ (1,0) [0|65535] "" ECU
 SG_ Sig03 : 55|16@0- (1,0) [-32768|32767] "" ECU

BO_ 600 Fixture088: 8 ECU
 SG_ Sig00 : 0|16@1+ (1,0) [0|65535] "" Tester
 SG_ Sig01 : 23|16@0- (1,0) [-32768|32767] "" Tester
 SG_ Sig02 : 32|16@1+ (1,0) [0|65535] "" Tester
 SG_ Sig03 : 55|16@0- (1,0) [-32768|32767] "" Tester

BO_ 601 Fixture089: 8 Tester
 SG_ Sig00 : 0|16@1+ (1,0) [0|65535] "" ECU
 SG_ Sig01 : 23|16@0- (1,0) [-32768|32767] "" ECU
 SG_ Sig02 : 32|16@1+ (1,0) [0|65535] "" ECU
 SG_ Sig03 : 55|16@0- (1,0) [-32768|32767] "" ECU

BO_ 602 Fixture090: 8 ECU
 SG_ Sig00 : 0|16@1+ (1,0) [0|65535] "" Tester
 SG_ Sig01 : 23|16@0- (1,0) [-32768|32767] "" Tester
 SG_ Sig02 : 32|16@1+ (1,0) [0|65535] "" Tester
 SG_ Sig03 : 55|16@0- (1,0) [-32768|32767] "" Tester

BO_ 603 Fixture091: 8 Tester
 SG_ Sig00 : 0|16@1+ (1,0) [0|65535] "" ECU
 SG_ Sig01 : 23|16@0- (1,0) [-32768|32767] "" ECU
 SG_ Sig02 : 32|16@1+ (1,0) [0|65535] "" ECU
 SG_ Sig03 : 55|16@0- (1,0) [-32768|32767] "" ECU

BO_ 604 Fixture092: 8 ECU
 SG_ Sig00 : 0|16@1+ (1,0) [0|65535] "" Tester
 SG_ Sig01 : 23|16@0- (1,0) [-32768|32767] "" Tester
 SG_ Sig02 : 32|16@1+ (1,0) [0|65535] "" Tester
 SG_ Sig03 : 55|16@0- (1,0) [-32768|32767] "" Tester

BO_ 605 Fixture093: 8 Tester
 SG_ Sig00 : 0|16@1+ (1,0) [0|65535] "" ECU
 SG_ Sig01 : 23|16@0- (1,0) [-32768|32767] "" ECU
 SG_ Sig02 : 32|16@1+ (1,0) [0|65535] "" ECU
 SG_ Sig03 : 55|16@0- (1,0) [-32768|32767] "" ECU

BO_ 606 Fixture094: 8 ECU
 SG_ Sig00 : 0|16@1+ (1,0) [0|65535] "" Tester
 SG_ Sig01 : 23|16@0- (1,0) [-32768|32767] "" Tester
 SG_ Sig02 : 32|16@1+ (1,0) [0|65535] "" Tester
 SG_ Sig03 : 55|16@0- (1,0) [-32768|32767] "" Tester

BO_ 607 Fixture095: 8 Tester
 SG_ Sig00 : 0|16@1+ (1,0) [0|65535] "" ECU
 SG_ Sig01 : 23|16@0- (1,0) [-32768|32767] "" ECU
 SG_ Sig02 : 32|16@1+ (1,0) [0|65535] "" ECU
 SG_ Sig03 : 55|16@0- (1,0) [-32768|32767] "" ECU

BO_ 608 Fixture096: 8 ECU
 SG_ Sig00 : 0|16@1+ (1,0) [0|65535] "" Tester
 SG_ Sig01 : 23|16@0- (1,0) [-32768|32767] "" Tester
 SG_ Sig02 : 32|16@1+ (1,0) [0|65535] "" Tester
 SG_ Sig03 : 55|16@0- (1,0) [-32768|32767] "" Tester

BO_ 609 Fixture097: 8 Tester
 SG_ Sig00 : 0|16@1+ (1,0) [0|65535] "" ECU
 SG_ Sig01 : 23|16@0- (1,0) [-32768|32767] "" ECU
 SG_ Sig02 : 32|16@1+ (1,0) [0|65535] "" ECU
 SG_ Sig03 : 55|16@0- (1,0) [-32768|32767] "" ECU

BO_ 610 Fixture098: 8 ECU
 SG_ Sig00 : 0|16@1+ (1,0) [0|65535] "" Tester
 SG_ Sig01 : 23|16@0- (1,0) [-32768|32767] "" Tester
 SG_ Sig02 : 32|16@1+ (1,0) [0|65535] "" Tester
 SG_ Sig03 : 55|16@0- (1,0) [-32768|32767] "" Tester

BO_ 611 Fixture099: 8 Tester
 SG_ Sig00 : 0|16@1+ (1,0) [0|65535] "" ECU
 SG_ Sig01 : 23|16@0- (1,0) [-32768|32767] "" ECU
 SG_ Sig02 : 32|16@1+ (1,0) [0|65535] "" ECU
 SG_ Sig03 : 55|16@0- (1,0) [-32768|32767] "" ECU
